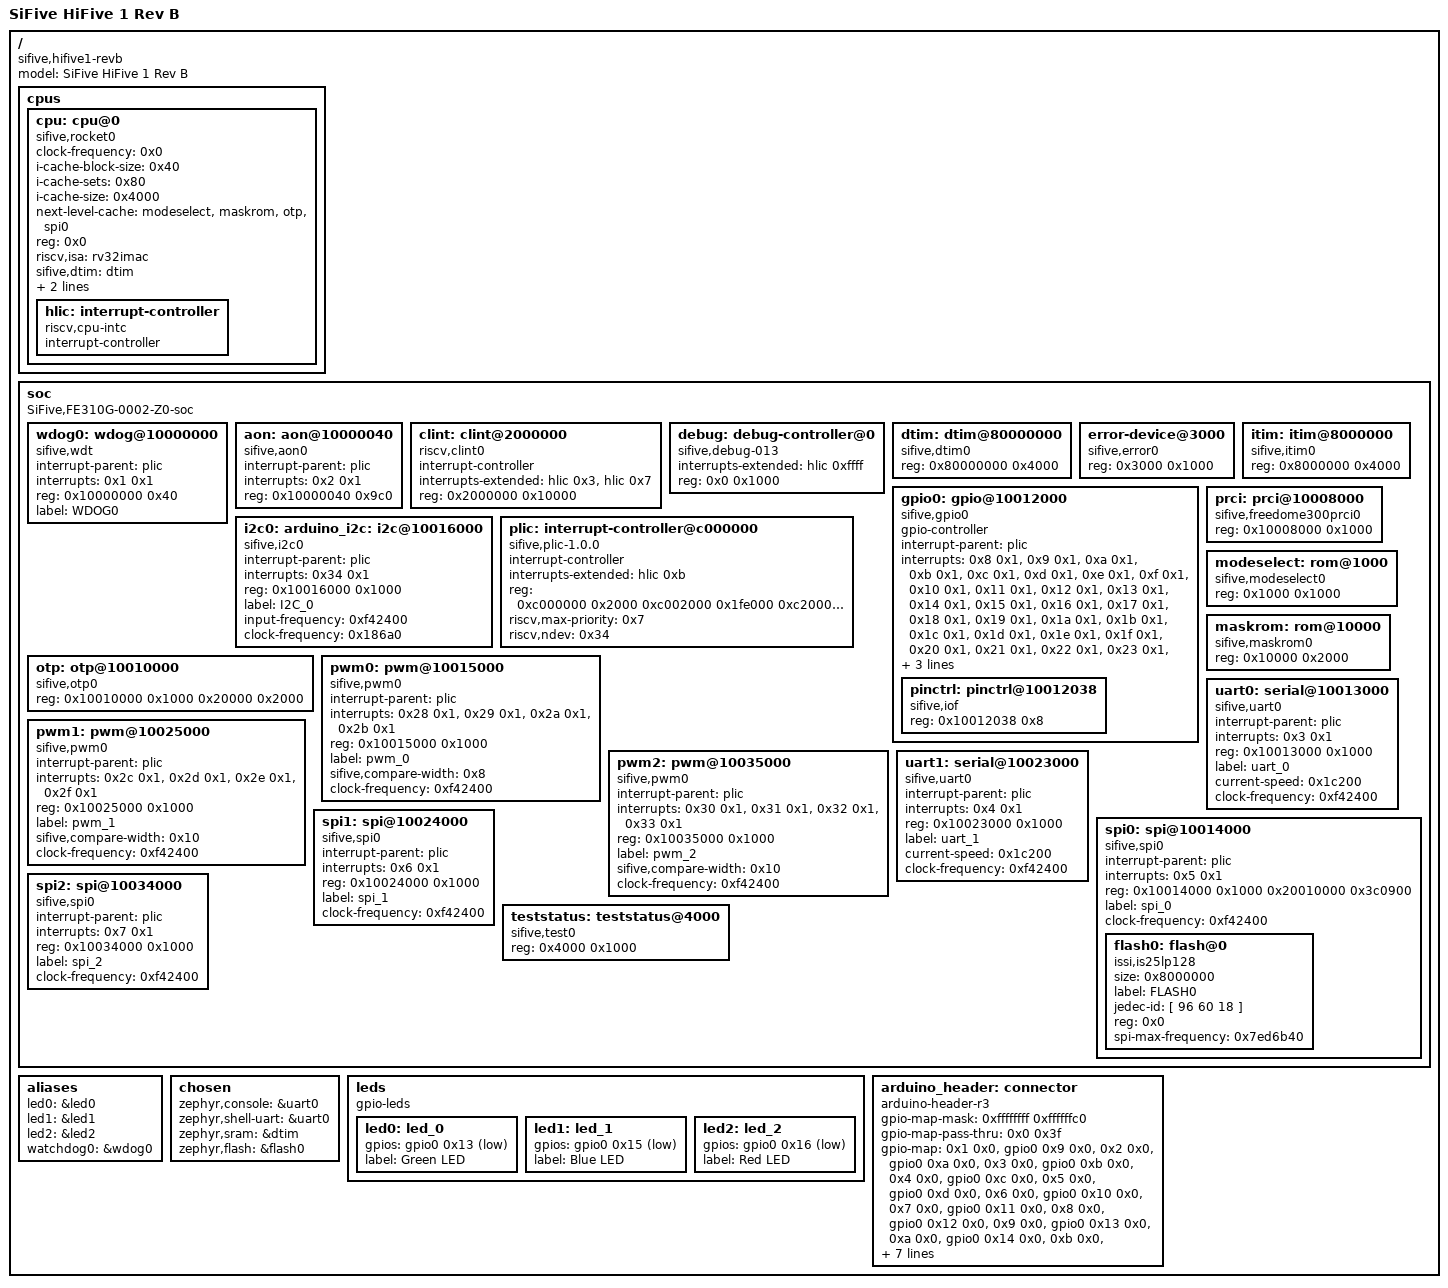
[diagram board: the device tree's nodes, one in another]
/dts-v1/;

/ {
	#address-cells = < 0x1 >;
	#size-cells = < 0x1 >;
	compatible = "sifive,hifive1-revb";
	model = "SiFive HiFive 1 Rev B";
	cpus {
		#address-cells = < 0x1 >;
		#size-cells = < 0x0 >;
		cpu: cpu@0 {
			clock-frequency = < 0x0 >;
			compatible = "sifive,rocket0", "riscv";
			device_type = "cpu";
			i-cache-block-size = < 0x40 >;
			i-cache-sets = < 0x80 >;
			i-cache-size = < 0x4000 >;
			next-level-cache = < &modeselect &maskrom &otp &spi0 >;
			reg = < 0x0 >;
			riscv,isa = "rv32imac";
			sifive,dtim = < &dtim >;
			sifive,itim = < &itim >;
			status = "okay";
			timebase-frequency = < 0x8000 >;
			hlic: interrupt-controller {
				#interrupt-cells = < 0x1 >;
				compatible = "riscv,cpu-intc";
				interrupt-controller;
				phandle = < 0x8 >;
			};
		};
	};
	soc {
		#address-cells = < 0x1 >;
		#size-cells = < 0x1 >;
		compatible = "SiFive,FE310G-0002-Z0-soc", "fe310-soc", "sifive-soc", "simple-bus";
		ranges;
		wdog0: wdog@10000000 {
			compatible = "sifive,wdt";
			interrupt-parent = < &plic >;
			interrupts = < 0x1 0x1 >;
			reg = < 0x10000000 0x40 >;
			reg-names = "control";
			label = "WDOG0";
		};
		aon: aon@10000040 {
			compatible = "sifive,aon0";
			interrupt-parent = < &plic >;
			interrupts = < 0x2 0x1 >;
			reg = < 0x10000040 0x9c0 >;
			reg-names = "control";
		};
		clint: clint@2000000 {
			#interrupt-cells = < 0x1 >;
			compatible = "riscv,clint0";
			interrupt-controller;
			interrupts-extended = < &hlic 0x3 &hlic 0x7 >;
			reg = < 0x2000000 0x10000 >;
			reg-names = "control";
		};
		debug: debug-controller@0 {
			compatible = "sifive,debug-013", "riscv,debug-013";
			interrupts-extended = < &hlic 0xffff >;
			reg = < 0x0 0x1000 >;
			reg-names = "control";
		};
		dtim: dtim@80000000 {
			compatible = "sifive,dtim0";
			reg = < 0x80000000 0x4000 >;
			reg-names = "mem";
			phandle = < 0x5 >;
		};
		error-device@3000 {
			compatible = "sifive,error0";
			reg = < 0x3000 0x1000 >;
			reg-names = "mem";
		};
		gpio0: gpio@10012000 {
			compatible = "sifive,gpio0";
			gpio-controller;
			interrupt-parent = < &plic >;
			interrupts = < 0x8 0x1 >, < 0x9 0x1 >, < 0xa 0x1 >, < 0xb 0x1 >, < 0xc 0x1 >, < 0xd 0x1 >, < 0xe 0x1 >, < 0xf 0x1 >, < 0x10 0x1 >, < 0x11 0x1 >, < 0x12 0x1 >, < 0x13 0x1 >, < 0x14 0x1 >, < 0x15 0x1 >, < 0x16 0x1 >, < 0x17 0x1 >, < 0x18 0x1 >, < 0x19 0x1 >, < 0x1a 0x1 >, < 0x1b 0x1 >, < 0x1c 0x1 >, < 0x1d 0x1 >, < 0x1e 0x1 >, < 0x1f 0x1 >, < 0x20 0x1 >, < 0x21 0x1 >, < 0x22 0x1 >, < 0x23 0x1 >, < 0x24 0x1 >, < 0x25 0x1 >, < 0x26 0x1 >, < 0x27 0x1 >;
			reg = < 0x10012000 0x1000 >;
			reg-names = "control";
			label = "gpio_0";
			status = "okay";
			#gpio-cells = < 0x2 >;
			#address-cells = < 0x1 >;
			#size-cells = < 0x1 >;
			ranges;
			phandle = < 0x9 >;
			pinctrl: pinctrl@10012038 {
				compatible = "sifive,iof";
				reg = < 0x10012038 0x8 >;
			};
		};
		i2c0: arduino_i2c: i2c@10016000 {
			compatible = "sifive,i2c0";
			interrupt-parent = < &plic >;
			interrupts = < 0x34 0x1 >;
			reg = < 0x10016000 0x1000 >;
			reg-names = "control";
			label = "I2C_0";
			status = "okay";
			#address-cells = < 0x1 >;
			#size-cells = < 0x0 >;
			input-frequency = < 0xf42400 >;
			clock-frequency = < 0x186a0 >;
		};
		plic: interrupt-controller@c000000 {
			#interrupt-cells = < 0x2 >;
			compatible = "sifive,plic-1.0.0";
			interrupt-controller;
			interrupts-extended = < &hlic 0xb >;
			reg = < 0xc000000 0x2000 0xc002000 0x1fe000 0xc200000 0x3e00000 >;
			reg-names = "prio", "irq_en", "reg";
			riscv,max-priority = < 0x7 >;
			riscv,ndev = < 0x34 >;
			phandle = < 0x7 >;
		};
		itim: itim@8000000 {
			compatible = "sifive,itim0";
			reg = < 0x8000000 0x4000 >;
			reg-names = "mem";
			phandle = < 0x6 >;
		};
		otp: otp@10010000 {
			compatible = "sifive,otp0";
			reg = < 0x10010000 0x1000 0x20000 0x2000 >;
			reg-names = "control", "mem";
			phandle = < 0x3 >;
		};
		prci: prci@10008000 {
			compatible = "sifive,freedome300prci0";
			reg = < 0x10008000 0x1000 >;
			reg-names = "control";
		};
		pwm0: pwm@10015000 {
			compatible = "sifive,pwm0";
			interrupt-parent = < &plic >;
			interrupts = < 0x28 0x1 >, < 0x29 0x1 >, < 0x2a 0x1 >, < 0x2b 0x1 >;
			reg = < 0x10015000 0x1000 >;
			reg-names = "control";
			label = "pwm_0";
			status = "okay";
			sifive,compare-width = < 0x8 >;
			#pwm-cells = < 0x2 >;
			clock-frequency = < 0xf42400 >;
		};
		pwm1: pwm@10025000 {
			compatible = "sifive,pwm0";
			interrupt-parent = < &plic >;
			interrupts = < 0x2c 0x1 >, < 0x2d 0x1 >, < 0x2e 0x1 >, < 0x2f 0x1 >;
			reg = < 0x10025000 0x1000 >;
			reg-names = "control";
			label = "pwm_1";
			status = "okay";
			sifive,compare-width = < 0x10 >;
			#pwm-cells = < 0x2 >;
			clock-frequency = < 0xf42400 >;
		};
		pwm2: pwm@10035000 {
			compatible = "sifive,pwm0";
			interrupt-parent = < &plic >;
			interrupts = < 0x30 0x1 >, < 0x31 0x1 >, < 0x32 0x1 >, < 0x33 0x1 >;
			reg = < 0x10035000 0x1000 >;
			reg-names = "control";
			label = "pwm_2";
			status = "okay";
			sifive,compare-width = < 0x10 >;
			#pwm-cells = < 0x2 >;
			clock-frequency = < 0xf42400 >;
		};
		modeselect: rom@1000 {
			compatible = "sifive,modeselect0";
			reg = < 0x1000 0x1000 >;
			reg-names = "mem";
			phandle = < 0x1 >;
		};
		maskrom: rom@10000 {
			compatible = "sifive,maskrom0";
			reg = < 0x10000 0x2000 >;
			reg-names = "mem";
			phandle = < 0x2 >;
		};
		uart0: serial@10013000 {
			compatible = "sifive,uart0";
			interrupt-parent = < &plic >;
			interrupts = < 0x3 0x1 >;
			reg = < 0x10013000 0x1000 >;
			reg-names = "control";
			label = "uart_0";
			status = "okay";
			current-speed = < 0x1c200 >;
			clock-frequency = < 0xf42400 >;
		};
		uart1: serial@10023000 {
			compatible = "sifive,uart0";
			interrupt-parent = < &plic >;
			interrupts = < 0x4 0x1 >;
			reg = < 0x10023000 0x1000 >;
			reg-names = "control";
			label = "uart_1";
			status = "okay";
			current-speed = < 0x1c200 >;
			clock-frequency = < 0xf42400 >;
		};
		spi0: spi@10014000 {
			compatible = "sifive,spi0";
			interrupt-parent = < &plic >;
			interrupts = < 0x5 0x1 >;
			reg = < 0x10014000 0x1000 0x20010000 0x3c0900 >;
			reg-names = "control", "mem";
			label = "spi_0";
			status = "okay";
			#address-cells = < 0x1 >;
			#size-cells = < 0x0 >;
			clock-frequency = < 0xf42400 >;
			phandle = < 0x4 >;
			flash0: flash@0 {
				compatible = "issi,is25lp128", "jedec,spi-nor";
				size = < 0x8000000 >;
				label = "FLASH0";
				jedec-id = [ 96 60 18 ];
				reg = < 0x0 >;
				spi-max-frequency = < 0x7ed6b40 >;
			};
		};
		spi1: spi@10024000 {
			compatible = "sifive,spi0";
			interrupt-parent = < &plic >;
			interrupts = < 0x6 0x1 >;
			reg = < 0x10024000 0x1000 >;
			reg-names = "control";
			label = "spi_1";
			status = "okay";
			#address-cells = < 0x1 >;
			#size-cells = < 0x0 >;
			clock-frequency = < 0xf42400 >;
		};
		spi2: spi@10034000 {
			compatible = "sifive,spi0";
			interrupt-parent = < &plic >;
			interrupts = < 0x7 0x1 >;
			reg = < 0x10034000 0x1000 >;
			reg-names = "control";
			label = "spi_2";
			status = "okay";
			#address-cells = < 0x1 >;
			#size-cells = < 0x0 >;
			clock-frequency = < 0xf42400 >;
		};
		teststatus: teststatus@4000 {
			compatible = "sifive,test0";
			reg = < 0x4000 0x1000 >;
			reg-names = "control";
		};
	};
	aliases {
		led0 = &led0;
		led1 = &led1;
		led2 = &led2;
		watchdog0 = &wdog0;
	};
	chosen {
		zephyr,console = &uart0;
		zephyr,shell-uart = &uart0;
		zephyr,sram = &dtim;
		zephyr,flash = &flash0;
	};
	leds {
		compatible = "gpio-leds";
		led0: led_0 {
			gpios = < &gpio0 0x13 0x1 >;
			label = "Green LED";
		};
		led1: led_1 {
			gpios = < &gpio0 0x15 0x1 >;
			label = "Blue LED";
		};
		led2: led_2 {
			gpios = < &gpio0 0x16 0x1 >;
			label = "Red LED";
		};
	};
	arduino_header: connector {
		compatible = "arduino-header-r3";
		#gpio-cells = < 0x2 >;
		gpio-map-mask = < 0xffffffff 0xffffffc0 >;
		gpio-map-pass-thru = < 0x0 0x3f >;
		gpio-map = < 0x1 0x0 &gpio0 0x9 0x0 >, < 0x2 0x0 &gpio0 0xa 0x0 >, < 0x3 0x0 &gpio0 0xb 0x0 >, < 0x4 0x0 &gpio0 0xc 0x0 >, < 0x5 0x0 &gpio0 0xd 0x0 >, < 0x6 0x0 &gpio0 0x10 0x0 >, < 0x7 0x0 &gpio0 0x11 0x0 >, < 0x8 0x0 &gpio0 0x12 0x0 >, < 0x9 0x0 &gpio0 0x13 0x0 >, < 0xa 0x0 &gpio0 0x14 0x0 >, < 0xb 0x0 &gpio0 0x15 0x0 >, < 0xc 0x0 &gpio0 0x16 0x0 >, < 0xd 0x0 &gpio0 0x17 0x0 >, < 0xe 0x0 &gpio0 0x0 0x0 >, < 0xf 0x0 &gpio0 0x1 0x0 >, < 0x10 0x0 &gpio0 0x2 0x0 >, < 0x11 0x0 &gpio0 0x3 0x0 >, < 0x12 0x0 &gpio0 0x4 0x0 >, < 0x13 0x0 &gpio0 0x5 0x0 >, < 0x14 0x0 &gpio0 0xc 0x0 >, < 0x15 0x0 &gpio0 0xd 0x0 >;
	};
};
